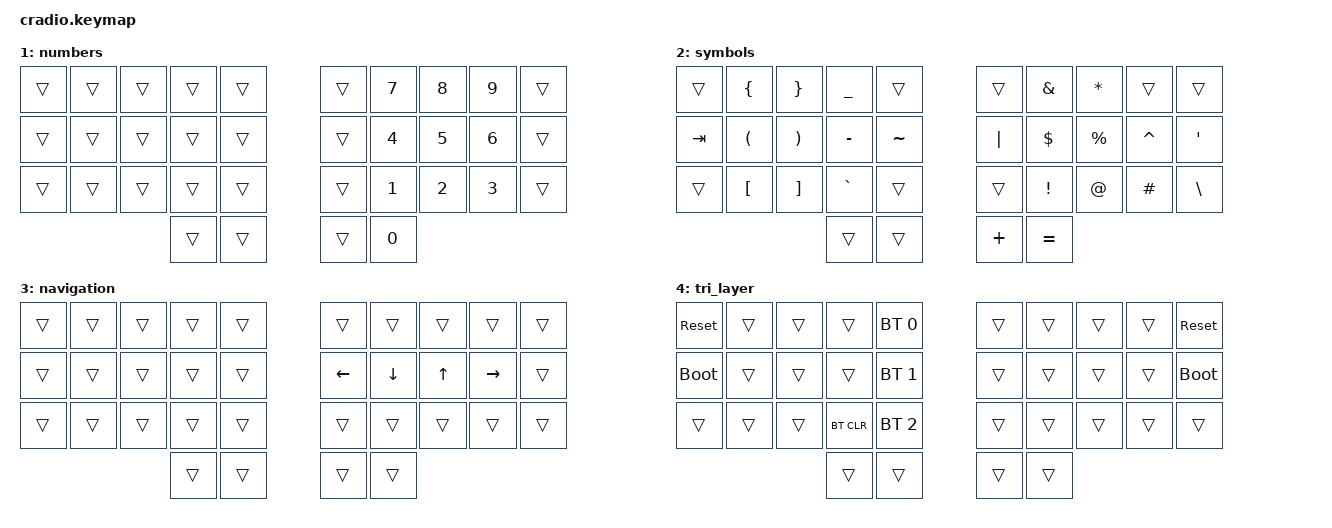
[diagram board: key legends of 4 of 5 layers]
// Copyright (c) 2022 The ZMK Contributors
// SPDX-License-Identifier: MIT

#include <behaviors.dtsi>
#include <dt-bindings/zmk/keys.h>
#include <dt-bindings/zmk/bt.h>

// Home row mods macro
#define HRML(k1,k2,k3,k4) &ht LSHFT k1  &ht LALT k2  &ht LCTRL k3  &ht LGUI k4
#define HRMR(k1,k2,k3,k4) &ht RGUI k1  &ht RCTRL k2  &ht RALT k3  &ht RSHFT k4

/ {
    behaviors {
        ht: hold_tap {
            compatible = "zmk,behavior-hold-tap";
            #binding-cells = <2>;
            flavor = "tap-preferred";
            tapping-term-ms = <220>;
            quick-tap-ms = <150>;
            require-prior-idle-ms = <100>;
            bindings = <&lt>, <&mo>;
        };

    };

    conditional_layers {
        compatible = "zmk,conditional-layers";
        tri_layer {
            if-layers = <1 2>;
            then-layer = <4>;
        };
    };

    keymap {
        compatible = "zmk,keymap";
        default_layer {
            bindings = <
        //╭──────────┬──────────┬──────────┬──────────┬──────────╮   ╭──────────┬──────────┬──────────┬──────────┬──────────╮
        //│  Q       │  W       │  F       │  P       │  B       │   │  J       │  L       │  U       │  Y       │  ;       │
            &kp Q      &kp W      &kp E      &kp R      &kp T          &kp Y      &kp U      &kp I      &kp O      &kp P
        //├──────────┼──────────┼──────────┼──────────┼──────────┤   ├──────────┼──────────┼──────────┼──────────┼──────────┤
        //│  A       │  R       │  S       │  T       │  G       │   │  M       │  N       │  E       │  I       │ O        │
            HRML(A,        S,         D,         F)     &kp G          &kp H      HRMR(J,        K,         L,        SEMI)
        //├──────────┼──────────┼──────────┼──────────┼──────────┤   ├──────────┼──────────┼──────────┼──────────┼──────────┤
        //│  Z       │  X       │  C       │  D       │  V       │   │  K       │  H       │ , <      │ . >      │ ?      │
            &kp Z      &kp X      &kp C      &kp V      &kp B          &kp N      &kp M      &kp COMMA  &kp DOT    &kp FSLH
        //╰──────────┴──────────┴──────────┼──────────┼──────────┤   ├──────────┼──────────┼──────────┴──────────┴──────────╯
                                            &ht 2 3 BSPC  &lt 1 ESC    &kp 3 ENTER  &kp SPACE
        //                                 ╰──────────┴──────────╯   ╰──────────┴──────────╯
            >;
        };

        numbers {
            bindings = <
        //╭──────────┬──────────┬──────────┬──────────┬──────────╮   ╭──────────┬──────────┬──────────┬──────────┬──────────╮
        //│          │          │          │          │          │              │ 7        │ 8        │ 9        │  
            &trans     &trans     &trans     &trans     &trans         &trans     &kp N7     &kp N8     &kp N9     &trans
        //├──────────┼──────────┼──────────┼──────────┼──────────┤   ├──────────┼──────────┼──────────┼──────────┼──────────┤
        //│          │          │          │          │          │   │          │ 4        │ 5        │ 6        │          │
            &trans     &trans     &trans     &trans     &trans         &trans     &kp N4     &kp N5     &kp N6     &trans
        //├──────────┼──────────┼──────────┼──────────┼──────────┤   ├──────────┼──────────┼──────────┼──────────┼──────────┤
        //│          │          │          │          │          │   │          │ 1        │ 2        │ 3        │          │
            &trans     &trans     &trans     &trans     &trans         &trans     &kp N1     &kp N2     &kp N3     &trans
        //╰──────────┴──────────┴──────────┼──────────┼──────────┤   ├──────────┼──────────┼──────────┴──────────┴──────────╯
                                             &trans     &trans         &trans     &kp N0
        //                                 ╰──────────┴──────────╯   ╰──────────┴──────────╯
            >;
        };

        symbols {
            bindings = <
        //╭──────────┬──────────┬──────────┬──────────┬──────────╮   ╭──────────┬──────────┬──────────┬──────────┬──────────╮
        //│          │ {        │ }        │ _        │          │              │ &        │ *        │          │   
            &trans     &kp LBRC   &kp RBRC   &kp UNDER  &trans         &trans     &kp AMPS   &kp ASTRK  &trans     &trans
        //├──────────┼──────────┼──────────┼──────────┼──────────┤   ├──────────┼──────────┼──────────┼──────────┼──────────┤
        //│          │ (        │ )        │ -        │ ~        │   │ |        │ $        │ %        │ ^        │ '        │
            &kp TAB    &kp LPAR   &kp RPAR   &kp MINUS  &kp TILDE      &kp PIPE   &kp DLLR   &kp PRCNT  &kp CARET  &kp SQT
        //├──────────┼──────────┼──────────┼──────────┼──────────┤   ├──────────┼──────────┼──────────┼──────────┼──────────┤
        //│          │ [        │ ]        │ `        │          │   │          │ !        │ @        │ #        │ \        │
            &trans     &kp LBKT   &kp RBKT   &kp GRAVE  &trans         &trans     &kp EXCL   &kp AT     &kp HASH   &kp BSLH
        //╰──────────┴──────────┴──────────┼──────────┼──────────┤   ├──────────┼──────────┼──────────┴──────────┴──────────╯
                                            &trans      &trans         &kp PLUS   &kp EQUAL
        //                                 ╰──────────┴──────────╯   ╰──────────┴──────────╯
            >;
        };

        navigation {
            bindings = <
        //╭──────────┬──────────┬──────────┬──────────┬──────────╮   ╭──────────┬──────────┬──────────┬──────────┬──────────╮
        //│          │          │          │          │          │   │          │          │          │          │          │
            &trans     &trans     &trans     &trans     &trans         &trans     &trans     &trans     &trans     &trans
        //├──────────┼──────────┼──────────┼──────────┼──────────┤   ├──────────┼──────────┼──────────┼──────────┼──────────┤
        //│          │          │          │          │          │   │ LEFT     │ DOWN     │ UP       │  RIGHT   │          │
            &trans     &trans     &trans     &trans     &trans         &kp LEFT   &kp DOWN   &kp UP     &kp RIGHT  &trans
        //├──────────┼──────────┼──────────┼──────────┼──────────┤   ├──────────┼──────────┼──────────┼──────────┼──────────┤
        //│          │          │          │          │          │   │          │          │          │          │          │
            &trans     &trans     &trans     &trans     &trans         &trans     &trans     &trans     &trans     &trans
        //╰──────────┴──────────┴──────────┼──────────┼──────────┤   ├──────────┼──────────┼──────────┴──────────┴──────────╯
                                             &trans     &trans         &trans     &trans
        //                                 ╰──────────┴──────────╯   ╰──────────┴──────────╯
            >;
        };

        tri_layer {
            bindings = <
        //╭──────────┬──────────┬──────────┬──────────┬──────────╮   ╭──────────┬──────────┬──────────┬──────────┬──────────╮
        //│ RESET    │          │          │          │PROFILE 0 │   │          │          │          │          │  RESET   │
           &sys_reset  &trans     &trans     &trans    &bt BT_SEL 0    &trans     &trans     &trans     &trans    &sys_reset
        //├──────────┼──────────┼──────────┼──────────┼──────────┤   ├──────────┼──────────┼──────────┼──────────┼──────────┤
        //│BOOTLOADER│          │          │          │PROFILE 1 │   │          │          │          │          │BOOTLOADER│
          &bootloader  &trans     &trans     &trans    &bt BT_SEL 1    &trans     &trans     &trans     &trans    &bootloader
        //├──────────┼──────────┼──────────┼──────────┼──────────┤   ├──────────┼──────────┼──────────┼──────────┼──────────┤
        //│          │          │          │ CLEAR BT │PROFILE 2 │   │          │          │          │          │          │
            &trans     &trans     &trans    &bt BT_CLR &bt BT_SEL 2    &trans     &trans     &trans     &trans     &trans
        //╰──────────┴──────────┴──────────┼──────────┼──────────┤   ├──────────┼──────────┼──────────┴──────────┴──────────╯
                                             &trans     &trans         &trans     &trans
        //                                 ╰──────────┴──────────╯   ╰──────────┴──────────╯
            >;
        };
    };
};
